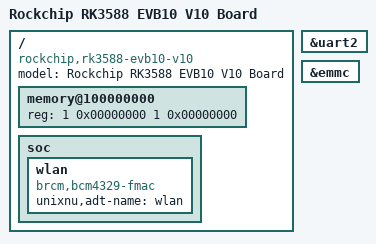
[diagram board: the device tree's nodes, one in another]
// SPDX-License-Identifier: BSD-2-Clause-Patent
/dts-v1/;
/include/ "rk3588.dtsi"

/ {
	model = "Rockchip RK3588 EVB10 V10 Board";
	compatible = "rockchip,rk3588-evb10-v10", "rockchip,rk3588";

	// The 4 GiB bank above 4 GiB is the one large region of the board's memory map without TF-A, OP-TEE,
	// firmware-volume or Rockchip carve-outs (low banks: 0x00200000-0x083fffff, 0x09400000-0xefffffff).
	memory@100000000 {
		device_type = "memory";
		reg = <1 0x00000000 1 0x00000000>;
	};
};

// Console (UART2 at 1.5 Mbaud, left configured by the firmware), the eMMC host and the Mali-G610.
// The Mali driver addresses the GPU by its fixed physical base, so its node stays disabled and is
// not exported to the Apple device tree.
&uart2 { status = "okay"; };
&emmc { status = "okay"; };

// The Wi-Fi module (an Ampak AP6398S on the SDIO host at 0xfe2d0000; package/Evb10Wifi addresses it by its fixed physical base, so the node has no
// registers and no interrupts). The node only has to exist in the Apple device tree: the userland's wifid is a launchd job limited to devices that
// have a node named "wlan" (_LimitLoadToDeviceTree), and without wifid the Settings Wi-Fi pane has nothing to talk to (docs/network.md).
/ {
	soc {
		wlan {
			compatible = "brcm,bcm4329-fmac";
			device_type = "wlan";
			unixnu,adt-name = "wlan";
		};
	};
};
